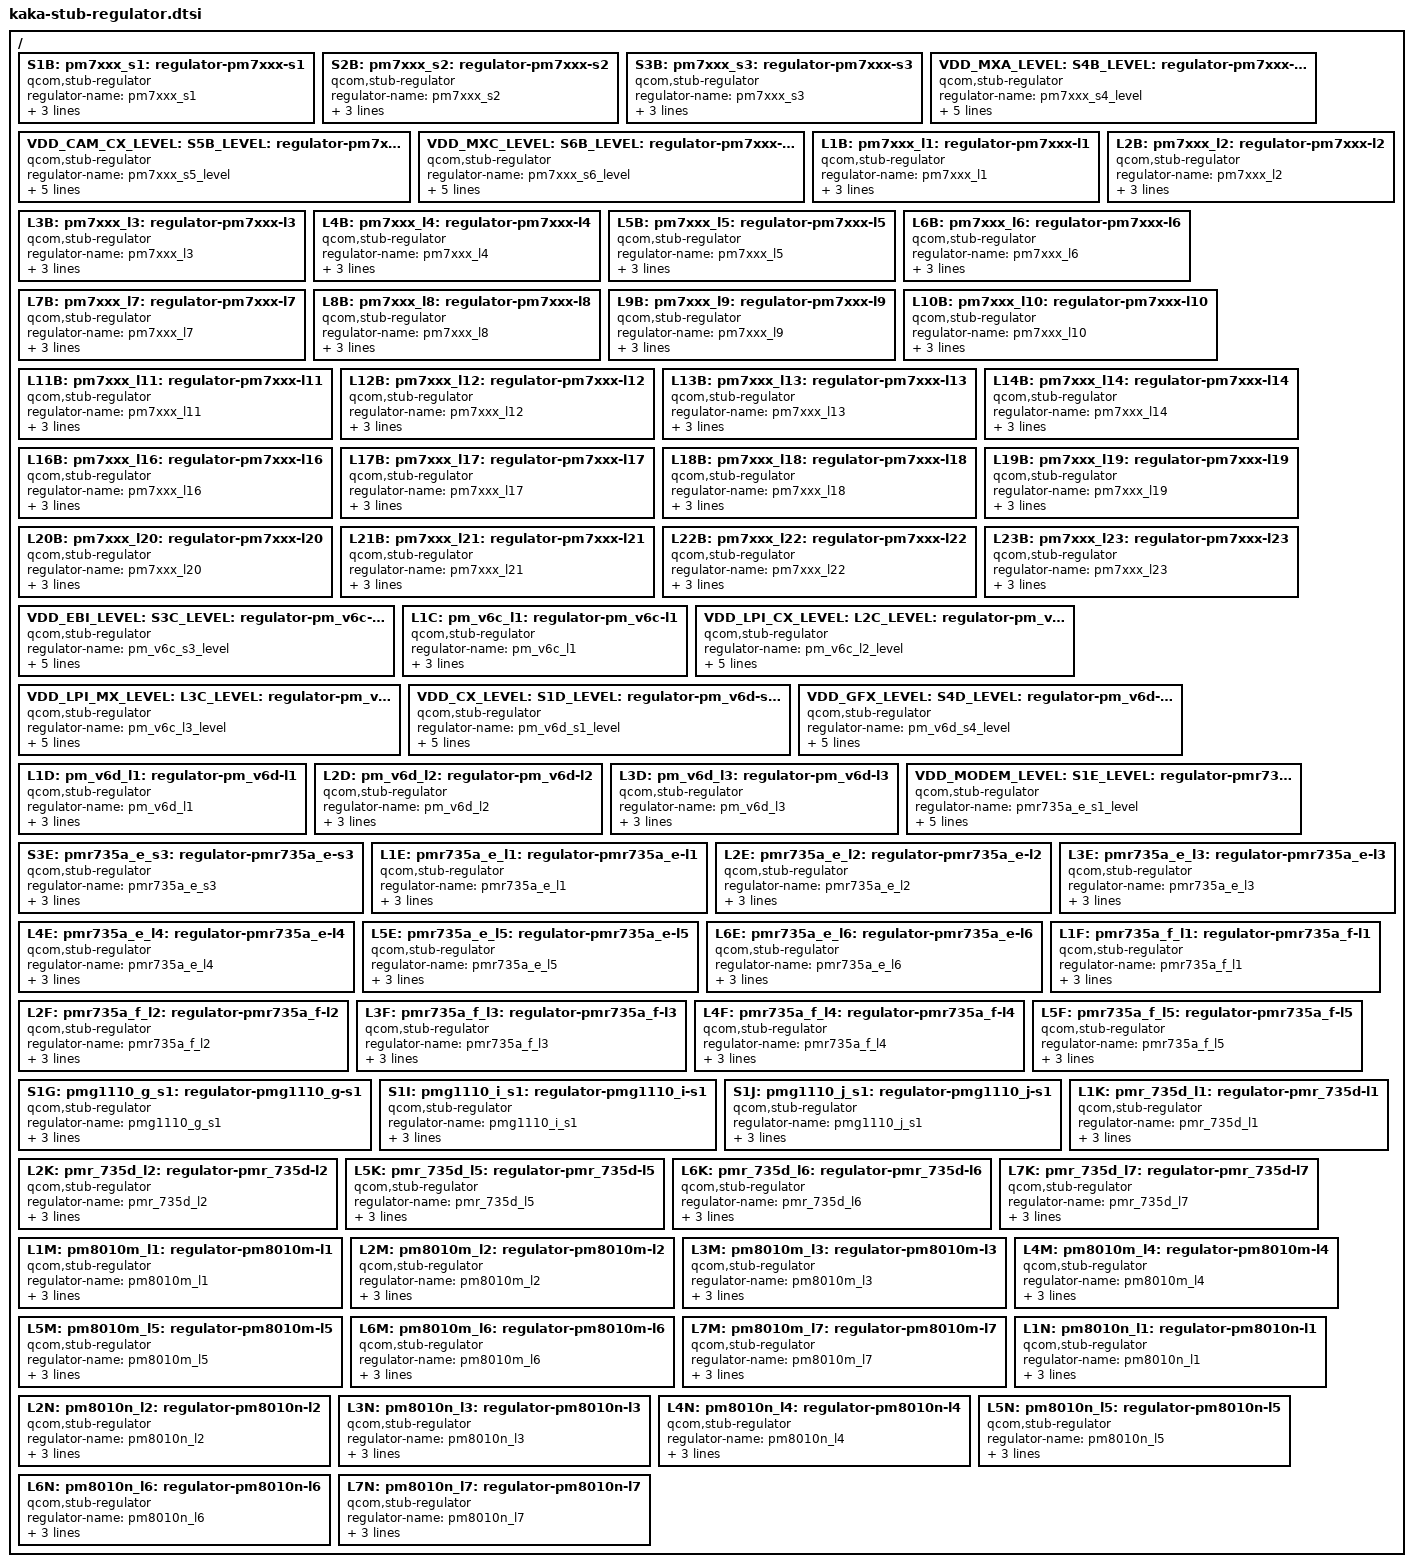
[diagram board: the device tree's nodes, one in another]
#include <dt-bindings/regulator/qcom,rpmh-regulator-levels.h>

/ {
	S1B:
	pm7xxx_s1: regulator-pm7xxx-s1 {
		compatible = "qcom,stub-regulator";
		regulator-name = "pm7xxx_s1";
		qcom,hpm-min-load = <10000>;
		regulator-min-microvolt = <1700000>;
		regulator-max-microvolt = <2040000>;
	};

	S2B:
	pm7xxx_s2: regulator-pm7xxx-s2 {
		compatible = "qcom,stub-regulator";
		regulator-name = "pm7xxx_s2";
		qcom,hpm-min-load = <10000>;
		regulator-min-microvolt = <1250000>;
		regulator-max-microvolt = <1980000>;
	};

	S3B:
	pm7xxx_s3: regulator-pm7xxx-s3 {
		compatible = "qcom,stub-regulator";
		regulator-name = "pm7xxx_s3";
		qcom,hpm-min-load = <10000>;
		regulator-min-microvolt = <690000>;
		regulator-max-microvolt = <1980000>;
	};

	VDD_MXA_LEVEL:
	S4B_LEVEL:
	pm7xxx_s4_level: regulator-pm7xxx-s4-level {
		compatible = "qcom,stub-regulator";
		regulator-name = "pm7xxx_s4_level";
		qcom,hpm-min-load = <10000>;
		regulator-min-microvolt =
			<RPMH_REGULATOR_LEVEL_RETENTION>;
		regulator-max-microvolt = <RPMH_REGULATOR_LEVEL_MAX>;
	};

	VDD_CAM_CX_LEVEL:
	S5B_LEVEL:
	pm7xxx_s5_level: regulator-pm7xxx-s5-level {
		compatible = "qcom,stub-regulator";
		regulator-name = "pm7xxx_s5_level";
		qcom,hpm-min-load = <10000>;
		regulator-min-microvolt =
			<RPMH_REGULATOR_LEVEL_RETENTION>;
		regulator-max-microvolt = <RPMH_REGULATOR_LEVEL_MAX>;
	};

	VDD_MXC_LEVEL:
	S6B_LEVEL:
	pm7xxx_s6_level: regulator-pm7xxx-s6-level {
		compatible = "qcom,stub-regulator";
		regulator-name = "pm7xxx_s6_level";
		qcom,hpm-min-load = <10000>;
		regulator-min-microvolt =
			<RPMH_REGULATOR_LEVEL_RETENTION>;
		regulator-max-microvolt = <RPMH_REGULATOR_LEVEL_MAX>;
	};

	L1B:
	pm7xxx_l1: regulator-pm7xxx-l1 {
		compatible = "qcom,stub-regulator";
		regulator-name = "pm7xxx_l1";
		qcom,hpm-min-load = <30000>;
		regulator-min-microvolt = <866000>;
		regulator-max-microvolt = <958000>;
	};

	L2B:
	pm7xxx_l2: regulator-pm7xxx-l2 {
		compatible = "qcom,stub-regulator";
		regulator-name = "pm7xxx_l2";
		qcom,hpm-min-load = <30000>;
		regulator-min-microvolt = <704000>;
		regulator-max-microvolt = <958000>;
	};

	L3B:
	pm7xxx_l3: regulator-pm7xxx-l3 {
		compatible = "qcom,stub-regulator";
		regulator-name = "pm7xxx_l3";
		qcom,hpm-min-load = <30000>;
		regulator-min-microvolt = <830000>;
		regulator-max-microvolt = <920000>;
	};

	L4B:
	pm7xxx_l4: regulator-pm7xxx-l4 {
		compatible = "qcom,stub-regulator";
		regulator-name = "pm7xxx_l4";
		qcom,hpm-min-load = <30000>;
		regulator-min-microvolt = <1080000>;
		regulator-max-microvolt = <1320000>;
	};

	L5B:
	pm7xxx_l5: regulator-pm7xxx-l5 {
		compatible = "qcom,stub-regulator";
		regulator-name = "pm7xxx_l5";
		qcom,hpm-min-load = <30000>;
		regulator-min-microvolt = <470000>;
		regulator-max-microvolt = <1980000>;
	};

	L6B:
	pm7xxx_l6: regulator-pm7xxx-l6 {
		compatible = "qcom,stub-regulator";
		regulator-name = "pm7xxx_l6";
		qcom,hpm-min-load = <30000>;
		regulator-min-microvolt = <1170000>;
		regulator-max-microvolt = <1900000>;
	};

	L7B:
	pm7xxx_l7: regulator-pm7xxx-l7 {
		compatible = "qcom,stub-regulator";
		regulator-name = "pm7xxx_l7";
		qcom,hpm-min-load = <30000>;
		regulator-min-microvolt = <320000>;
		regulator-max-microvolt = <2000000>;
	};

	L8B:
	pm7xxx_l8: regulator-pm7xxx-l8 {
		compatible = "qcom,stub-regulator";
		regulator-name = "pm7xxx_l8";
		qcom,hpm-min-load = <30000>;
		regulator-min-microvolt = <1700000>;
		regulator-max-microvolt = <1900000>;
	};

	L9B:
	pm7xxx_l9: regulator-pm7xxx-l9 {
		compatible = "qcom,stub-regulator";
		regulator-name = "pm7xxx_l9";
		qcom,hpm-min-load = <30000>;
		regulator-min-microvolt = <1650000>;
		regulator-max-microvolt = <2000000>;
	};

	L10B:
	pm7xxx_l10: regulator-pm7xxx-l10 {
		compatible = "qcom,stub-regulator";
		regulator-name = "pm7xxx_l10";
		qcom,hpm-min-load = <30000>;
		regulator-min-microvolt = <1080000>;
		regulator-max-microvolt = <2000000>;
	};

	L11B:
	pm7xxx_l11: regulator-pm7xxx-l11 {
		compatible = "qcom,stub-regulator";
		regulator-name = "pm7xxx_l11";
		qcom,hpm-min-load = <30000>;
		regulator-min-microvolt = <1620000>;
		regulator-max-microvolt = <1980000>;
	};

	L12B:
	pm7xxx_l12: regulator-pm7xxx-l12 {
		compatible = "qcom,stub-regulator";
		regulator-name = "pm7xxx_l12";
		qcom,hpm-min-load = <10000>;
		regulator-min-microvolt = <2400000>;
		regulator-max-microvolt = <3300000>;
	};

	L13B:
	pm7xxx_l13: regulator-pm7xxx-l13 {
		compatible = "qcom,stub-regulator";
		regulator-name = "pm7xxx_l13";
		qcom,hpm-min-load = <10000>;
		regulator-min-microvolt = <1800000>;
		regulator-max-microvolt = <3300000>;
	};

	L14B:
	pm7xxx_l14: regulator-pm7xxx-l14 {
		compatible = "qcom,stub-regulator";
		regulator-name = "pm7xxx_l14";
		qcom,hpm-min-load = <10000>;
		regulator-min-microvolt = <1504000>;
		regulator-max-microvolt = <3544000>;
	};

	L16B:
	pm7xxx_l16: regulator-pm7xxx-l16 {
		compatible = "qcom,stub-regulator";
		regulator-name = "pm7xxx_l16";
		qcom,hpm-min-load = <10000>;
		regulator-min-microvolt = <3000000>;
		regulator-max-microvolt = <3544000>;
	};

	L17B:
	pm7xxx_l17: regulator-pm7xxx-l17 {
		compatible = "qcom,stub-regulator";
		regulator-name = "pm7xxx_l17";
		qcom,hpm-min-load = <10000>;
		regulator-min-microvolt = <2700000>;
		regulator-max-microvolt = <3544000>;
	};

	L18B:
	pm7xxx_l18: regulator-pm7xxx-l18 {
		compatible = "qcom,stub-regulator";
		regulator-name = "pm7xxx_l18";
		qcom,hpm-min-load = <10000>;
		regulator-min-microvolt = <1650000>;
		regulator-max-microvolt = <3544000>;
	};

	L19B:
	pm7xxx_l19: regulator-pm7xxx-l19 {
		compatible = "qcom,stub-regulator";
		regulator-name = "pm7xxx_l19";
		qcom,hpm-min-load = <10000>;
		regulator-min-microvolt = <2700000>;
		regulator-max-microvolt = <3544000>;
	};

	L20B:
	pm7xxx_l20: regulator-pm7xxx-l20 {
		compatible = "qcom,stub-regulator";
		regulator-name = "pm7xxx_l20";
		qcom,hpm-min-load = <10000>;
		regulator-min-microvolt = <1620000>;
		regulator-max-microvolt = <3544000>;
	};

	L21B:
	pm7xxx_l21: regulator-pm7xxx-l21 {
		compatible = "qcom,stub-regulator";
		regulator-name = "pm7xxx_l21";
		qcom,hpm-min-load = <10000>;
		regulator-min-microvolt = <1620000>;
		regulator-max-microvolt = <3544000>;
	};

	L22B:
	pm7xxx_l22: regulator-pm7xxx-l22 {
		compatible = "qcom,stub-regulator";
		regulator-name = "pm7xxx_l22";
		qcom,hpm-min-load = <10000>;
		regulator-min-microvolt = <2700000>;
		regulator-max-microvolt = <3544000>;
	};

	L23B:
	pm7xxx_l23: regulator-pm7xxx-l23 {
		compatible = "qcom,stub-regulator";
		regulator-name = "pm7xxx_l23";
		qcom,hpm-min-load = <10000>;
		regulator-min-microvolt = <1650000>;
		regulator-max-microvolt = <3544000>;
	};

	VDD_EBI_LEVEL:
	S3C_LEVEL:
	pm_v6c_s3_level: regulator-pm_v6c-s3-level {
		compatible = "qcom,stub-regulator";
		regulator-name = "pm_v6c_s3_level";
		qcom,hpm-min-load = <10000>;
		regulator-min-microvolt =
			<RPMH_REGULATOR_LEVEL_RETENTION>;
		regulator-max-microvolt = <RPMH_REGULATOR_LEVEL_MAX>;
	};

	L1C:
	pm_v6c_l1: regulator-pm_v6c-l1 {
		compatible = "qcom,stub-regulator";
		regulator-name = "pm_v6c_l1";
		qcom,hpm-min-load = <30000>;
		regulator-min-microvolt = <320000>;
		regulator-max-microvolt = <570000>;
	};

	VDD_LPI_CX_LEVEL:
	L2C_LEVEL:
	pm_v6c_l2_level: regulator-pm_v6c-l2-level {
		compatible = "qcom,stub-regulator";
		regulator-name = "pm_v6c_l2_level";
		qcom,hpm-min-load = <30000>;
		regulator-min-microvolt =
			<RPMH_REGULATOR_LEVEL_RETENTION>;
		regulator-max-microvolt = <RPMH_REGULATOR_LEVEL_MAX>;
	};

	VDD_LPI_MX_LEVEL:
	L3C_LEVEL:
	pm_v6c_l3_level: regulator-pm_v6c-l3-level {
		compatible = "qcom,stub-regulator";
		regulator-name = "pm_v6c_l3_level";
		qcom,hpm-min-load = <30000>;
		regulator-min-microvolt =
			<RPMH_REGULATOR_LEVEL_RETENTION>;
		regulator-max-microvolt = <RPMH_REGULATOR_LEVEL_MAX>;
	};

	VDD_CX_LEVEL:
	S1D_LEVEL:
	pm_v6d_s1_level: regulator-pm_v6d-s1-level {
		compatible = "qcom,stub-regulator";
		regulator-name = "pm_v6d_s1_level";
		qcom,hpm-min-load = <10000>;
		regulator-min-microvolt =
			<RPMH_REGULATOR_LEVEL_RETENTION>;
		regulator-max-microvolt = <RPMH_REGULATOR_LEVEL_MAX>;
	};

	VDD_GFX_LEVEL:
	S4D_LEVEL:
	pm_v6d_s4_level: regulator-pm_v6d-s4-level {
		compatible = "qcom,stub-regulator";
		regulator-name = "pm_v6d_s4_level";
		qcom,hpm-min-load = <10000>;
		regulator-min-microvolt =
			<RPMH_REGULATOR_LEVEL_RETENTION>;
		regulator-max-microvolt = <RPMH_REGULATOR_LEVEL_MAX>;
	};

	L1D:
	pm_v6d_l1: regulator-pm_v6d-l1 {
		compatible = "qcom,stub-regulator";
		regulator-name = "pm_v6d_l1";
		qcom,hpm-min-load = <30000>;
		regulator-min-microvolt = <870000>;
		regulator-max-microvolt = <970000>;
	};

	L2D:
	pm_v6d_l2: regulator-pm_v6d-l2 {
		compatible = "qcom,stub-regulator";
		regulator-name = "pm_v6d_l2";
		qcom,hpm-min-load = <30000>;
		regulator-min-microvolt = <1140000>;
		regulator-max-microvolt = <1950000>;
	};

	L3D:
	pm_v6d_l3: regulator-pm_v6d-l3 {
		compatible = "qcom,stub-regulator";
		regulator-name = "pm_v6d_l3";
		qcom,hpm-min-load = <30000>;
		regulator-min-microvolt = <1100000>;
		regulator-max-microvolt = <1300000>;
	};

	VDD_MODEM_LEVEL:
	S1E_LEVEL:
	pmr735a_e_s1_level: regulator-pmr735a_e-s1-level {
		compatible = "qcom,stub-regulator";
		regulator-name = "pmr735a_e_s1_level";
		qcom,hpm-min-load = <10000>;
		regulator-min-microvolt =
			<RPMH_REGULATOR_LEVEL_RETENTION>;
		regulator-max-microvolt = <RPMH_REGULATOR_LEVEL_MAX>;
	};

	S3E:
	pmr735a_e_s3: regulator-pmr735a_e-s3 {
		compatible = "qcom,stub-regulator";
		regulator-name = "pmr735a_e_s3";
		qcom,hpm-min-load = <10000>;
		regulator-min-microvolt = <806000>;
		regulator-max-microvolt = <2400000>;
	};

	L1E:
	pmr735a_e_l1: regulator-pmr735a_e-l1 {
		compatible = "qcom,stub-regulator";
		regulator-name = "pmr735a_e_l1";
		qcom,hpm-min-load = <30000>;
		regulator-min-microvolt = <1080000>;
		regulator-max-microvolt = <1304000>;
	};

	L2E:
	pmr735a_e_l2: regulator-pmr735a_e-l2 {
		compatible = "qcom,stub-regulator";
		regulator-name = "pmr735a_e_l2";
		qcom,hpm-min-load = <30000>;
		regulator-min-microvolt = <1100000>;
		regulator-max-microvolt = <1304000>;
	};

	L3E:
	pmr735a_e_l3: regulator-pmr735a_e-l3 {
		compatible = "qcom,stub-regulator";
		regulator-name = "pmr735a_e_l3";
		qcom,hpm-min-load = <30000>;
		regulator-min-microvolt = <866000>;
		regulator-max-microvolt = <950000>;
	};

	L4E:
	pmr735a_e_l4: regulator-pmr735a_e-l4 {
		compatible = "qcom,stub-regulator";
		regulator-name = "pmr735a_e_l4";
		qcom,hpm-min-load = <10000>;
		regulator-min-microvolt = <1600000>;
		regulator-max-microvolt = <2000000>;
	};

	L5E:
	pmr735a_e_l5: regulator-pmr735a_e-l5 {
		compatible = "qcom,stub-regulator";
		regulator-name = "pmr735a_e_l5";
		qcom,hpm-min-load = <30000>;
		regulator-min-microvolt = <751000>;
		regulator-max-microvolt = <824000>;
	};

	L6E:
	pmr735a_e_l6: regulator-pmr735a_e-l6 {
		compatible = "qcom,stub-regulator";
		regulator-name = "pmr735a_e_l6";
		qcom,hpm-min-load = <30000>;
		regulator-min-microvolt = <530000>;
		regulator-max-microvolt = <864000>;
	};

	L1F:
	pmr735a_f_l1: regulator-pmr735a_f-l1 {
		compatible = "qcom,stub-regulator";
		regulator-name = "pmr735a_f_l1";
		qcom,hpm-min-load = <30000>;
		regulator-min-microvolt = <866000>;
		regulator-max-microvolt = <939000>;
	};

	L2F:
	pmr735a_f_l2: regulator-pmr735a_f-l2 {
		compatible = "qcom,stub-regulator";
		regulator-name = "pmr735a_f_l2";
		qcom,hpm-min-load = <30000>;
		regulator-min-microvolt = <760000>;
		regulator-max-microvolt = <824000>;
	};

	L3F:
	pmr735a_f_l3: regulator-pmr735a_f-l3 {
		compatible = "qcom,stub-regulator";
		regulator-name = "pmr735a_f_l3";
		qcom,hpm-min-load = <30000>;
		regulator-min-microvolt = <588000>;
		regulator-max-microvolt = <800000>;
	};

	L4F:
	pmr735a_f_l4: regulator-pmr735a_f-l4 {
		compatible = "qcom,stub-regulator";
		regulator-name = "pmr735a_f_l4";
		qcom,hpm-min-load = <10000>;
		regulator-min-microvolt = <1710000>;
		regulator-max-microvolt = <1854000>;
	};

	L5F:
	pmr735a_f_l5: regulator-pmr735a_f-l5 {
		compatible = "qcom,stub-regulator";
		regulator-name = "pmr735a_f_l5";
		qcom,hpm-min-load = <30000>;
		regulator-min-microvolt = <1140000>;
		regulator-max-microvolt = <1236000>;
	};

	S1G:
	pmg1110_g_s1: regulator-pmg1110_g-s1 {
		compatible = "qcom,stub-regulator";
		regulator-name = "pmg1110_g_s1";
		qcom,hpm-min-load = <10000>;
		regulator-min-microvolt = <806000>;
		regulator-max-microvolt = <1003000>;
	};

	S1I:
	pmg1110_i_s1: regulator-pmg1110_i-s1 {
		compatible = "qcom,stub-regulator";
		regulator-name = "pmg1110_i_s1";
		qcom,hpm-min-load = <10000>;
		regulator-min-microvolt = <320000>;
		regulator-max-microvolt = <570000>;
	};

	S1J:
	pmg1110_j_s1: regulator-pmg1110_j-s1 {
		compatible = "qcom,stub-regulator";
		regulator-name = "pmg1110_j_s1";
		qcom,hpm-min-load = <10000>;
		regulator-min-microvolt = <1010000>;
		regulator-max-microvolt = <1170000>;
	};

	L1K:
	pmr_735d_l1: regulator-pmr_735d-l1 {
		compatible = "qcom,stub-regulator";
		regulator-name = "pmr_735d_l1";
		qcom,hpm-min-load = <10000>;
		regulator-min-microvolt = <866000>;
		regulator-max-microvolt = <950000>;
	};

	L2K:
	pmr_735d_l2: regulator-pmr_735d-l2 {
		compatible = "qcom,stub-regulator";
		regulator-name = "pmr_735d_l2";
		qcom,hpm-min-load = <10000>;
		regulator-min-microvolt = <530000>;
		regulator-max-microvolt = <864000>;
	};

	L5K:
	pmr_735d_l5: regulator-pmr_735d-l5 {
		compatible = "qcom,stub-regulator";
		regulator-name = "pmr_735d_l5";
		qcom,hpm-min-load = <10000>;
		regulator-min-microvolt = <751000>;
		regulator-max-microvolt = <824000>;
	};

	L6K:
	pmr_735d_l6: regulator-pmr_735d-l6 {
		compatible = "qcom,stub-regulator";
		regulator-name = "pmr_735d_l6";
		qcom,hpm-min-load = <10000>;
		regulator-min-microvolt = <1698000>;
		regulator-max-microvolt = <1957000>;
	};

	L7K:
	pmr_735d_l7: regulator-pmr_735d-l7 {
		compatible = "qcom,stub-regulator";
		regulator-name = "pmr_735d_l7";
		qcom,hpm-min-load = <10000>;
		regulator-min-microvolt = <1139000>;
		regulator-max-microvolt = <1236000>;
	};

	L1M:
	pm8010m_l1: regulator-pm8010m-l1 {
		compatible = "qcom,stub-regulator";
		regulator-name = "pm8010m_l1";
		qcom,hpm-min-load = <10000>;
		regulator-min-microvolt = <1050000>;
		regulator-max-microvolt = <1180000>;
	};

	L2M:
	pm8010m_l2: regulator-pm8010m-l2 {
		compatible = "qcom,stub-regulator";
		regulator-name = "pm8010m_l2";
		qcom,hpm-min-load = <10000>;
		regulator-min-microvolt = <950000>;
		regulator-max-microvolt = <1150000>;
	};

	L3M:
	pm8010m_l3: regulator-pm8010m-l3 {
		compatible = "qcom,stub-regulator";
		regulator-name = "pm8010m_l3";
		qcom,hpm-min-load = <10000>;
		regulator-min-microvolt = <2700000>;
		regulator-max-microvolt = <2900000>;
	};

	L4M:
	pm8010m_l4: regulator-pm8010m-l4 {
		compatible = "qcom,stub-regulator";
		regulator-name = "pm8010m_l4";
		qcom,hpm-min-load = <10000>;
		regulator-min-microvolt = <2700000>;
		regulator-max-microvolt = <2900000>;
	};

	L5M:
	pm8010m_l5: regulator-pm8010m-l5 {
		compatible = "qcom,stub-regulator";
		regulator-name = "pm8010m_l5";
		qcom,hpm-min-load = <10000>;
		regulator-min-microvolt = <1700000>;
		regulator-max-microvolt = <1900000>;
	};

	L6M:
	pm8010m_l6: regulator-pm8010m-l6 {
		compatible = "qcom,stub-regulator";
		regulator-name = "pm8010m_l6";
		qcom,hpm-min-load = <10000>;
		regulator-min-microvolt = <2700000>;
		regulator-max-microvolt = <2900000>;
	};

	L7M:
	pm8010m_l7: regulator-pm8010m-l7 {
		compatible = "qcom,stub-regulator";
		regulator-name = "pm8010m_l7";
		qcom,hpm-min-load = <10000>;
		regulator-min-microvolt = <2700000>;
		regulator-max-microvolt = <3000000>;
	};

	L1N:
	pm8010n_l1: regulator-pm8010n-l1 {
		compatible = "qcom,stub-regulator";
		regulator-name = "pm8010n_l1";
		qcom,hpm-min-load = <10000>;
		regulator-min-microvolt = <1050000>;
		regulator-max-microvolt = <1200000>;
	};

	L2N:
	pm8010n_l2: regulator-pm8010n-l2 {
		compatible = "qcom,stub-regulator";
		regulator-name = "pm8010n_l2";
		qcom,hpm-min-load = <10000>;
		regulator-min-microvolt = <950000>;
		regulator-max-microvolt = <1150000>;
	};

	L3N:
	pm8010n_l3: regulator-pm8010n-l3 {
		compatible = "qcom,stub-regulator";
		regulator-name = "pm8010n_l3";
		qcom,hpm-min-load = <10000>;
		regulator-min-microvolt = <1792000>;
		regulator-max-microvolt = <1900000>;
	};

	L4N:
	pm8010n_l4: regulator-pm8010n-l4 {
		compatible = "qcom,stub-regulator";
		regulator-name = "pm8010n_l4";
		qcom,hpm-min-load = <10000>;
		regulator-min-microvolt = <1792000>;
		regulator-max-microvolt = <1900000>;
	};

	L5N:
	pm8010n_l5: regulator-pm8010n-l5 {
		compatible = "qcom,stub-regulator";
		regulator-name = "pm8010n_l5";
		qcom,hpm-min-load = <10000>;
		regulator-min-microvolt = <2700000>;
		regulator-max-microvolt = <2900000>;
	};

	L6N:
	pm8010n_l6: regulator-pm8010n-l6 {
		compatible = "qcom,stub-regulator";
		regulator-name = "pm8010n_l6";
		qcom,hpm-min-load = <10000>;
		regulator-min-microvolt = <1792000>;
		regulator-max-microvolt = <1900000>;
	};

	L7N:
	pm8010n_l7: regulator-pm8010n-l7 {
		compatible = "qcom,stub-regulator";
		regulator-name = "pm8010n_l7";
		qcom,hpm-min-load = <10000>;
		regulator-min-microvolt = <2700000>;
		regulator-max-microvolt = <3000000>;
	};
};
